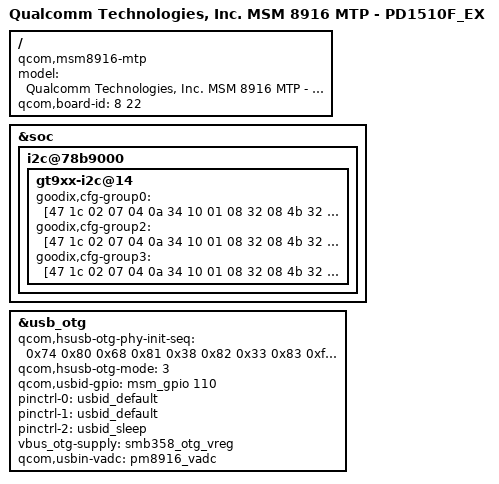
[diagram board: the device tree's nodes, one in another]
/*
 * Copyright (c) 2014-2018, The Linux Foundation. All rights reserved.
 *
 * This program is free software; you can redistribute it and/or modify
 * it under the terms of the GNU General Public License version 2 and
 * only version 2 as published by the Free Software Foundation.
 *
 * This program is distributed in the hope that it will be useful,
 * but WITHOUT ANY WARRANTY; without even the implied warranty of
 * MERCHANTABILITY or FITNESS FOR A PARTICULAR PURPOSE.  See the
 * GNU General Public License for more details.
 */

/dts-v1/;

#include "msm8916-mtp.dtsi"
#include "msm8916-memory.dtsi"
#include "pd1510/msm8916-mtp-pd1510.dtsi"

/ {
	model = "Qualcomm Technologies, Inc. MSM 8916 MTP - PD1510F_EX";
	compatible = "qcom,msm8916-mtp", "qcom,msm8916", "qcom,mtp";
	qcom,board-id = <8 22>;
};

&soc {
	i2c@78b9000 {
		gt9xx-i2c@14 {
			goodix,cfg-group0 = [47 1c 02 07 04 0a 34 10 01 08 32 08 4b 32 33 35 00 00 37 13 00 10 00 14 14 26 14 8c 2c 0d 46 48 d3 07 d3 07 00 99 33 11 00 00 00 00 00 00 00 08 0a a0 21 28 5f 94 d0 02 3c 1e 00 04 d0 2b 00 b1 34 1e 9c 3d 00 88 49 00 78 57 00 78 00 00 00 00 00 00 00 00 00 00 00 00 00 00 00 00 00 00 f7 01 00 00 00 00 00 00 00 00 00 14 50 00 00 00 00 1e 1a 18 16 14 12 10 0e 0c 0a 08 06 04 02 ff 00 00 00 00 00 00 00 00 08 00 00 00 de 00 00 41 16 18 1c 1d 1e 1f 20 21 22 24 26 28 14 13 12 10 0f 0c 0a 08 06 04 02 00 ff ff 00 00 00 00 00 00 00 00 00 00 00 00 00 00 00 00 1e 01];
			goodix,cfg-group2 = [47 1c 02 07 04 0a 34 10 01 08 32 08 4b 32 33 35 00 00 37 13 00 10 00 14 14 26 14 8c 2c 0d 46 48 d3 07 d3 07 00 99 33 11 00 00 00 00 00 00 00 08 0a a0 21 28 5f 94 d0 02 3c 1e 00 04 d0 2b 00 b1 34 1e 9c 3d 00 88 49 00 78 57 00 78 00 00 00 00 00 00 00 00 00 00 00 00 00 00 00 00 00 00 f7 01 00 00 00 00 00 00 00 00 00 14 50 00 00 00 00 1e 1a 18 16 14 12 10 0e 0c 0a 08 06 04 02 ff 00 00 00 00 00 00 00 00 08 00 00 00 de 00 00 41 16 18 1c 1d 1e 1f 20 21 22 24 26 28 14 13 12 10 0f 0c 0a 08 06 04 02 00 ff ff 00 00 00 00 00 00 00 00 00 00 00 00 00 00 00 00 1e 01];
			goodix,cfg-group3 = [47 1c 02 07 04 0a 34 10 01 08 32 08 4b 32 33 35 00 00 37 13 00 10 00 14 14 26 14 8c 2c 0d 46 48 d3 07 d3 07 00 99 33 11 00 00 00 00 00 00 00 08 0a a0 21 28 5f 94 d0 02 3c 1e 00 04 d0 2b 00 b1 34 1e 9c 3d 00 88 49 00 78 57 00 78 00 00 00 00 00 00 00 00 00 00 00 00 00 00 00 00 00 00 f7 01 00 00 00 00 00 00 00 00 00 14 50 00 00 00 00 1e 1a 18 16 14 12 10 0e 0c 0a 08 06 04 02 ff 00 00 00 00 00 00 00 00 08 00 00 00 de 00 00 41 16 18 1c 1d 1e 1f 20 21 22 24 26 28 14 13 12 10 0f 0c 0a 08 06 04 02 00 ff ff 00 00 00 00 00 00 00 00 00 00 00 00 00 00 00 00 1e 01];
		};
	};
};

&usb_otg {
	qcom,hsusb-otg-phy-init-seq = <0x74 0x80 0x68 0x81 0x38 0x82 0x33 0x83 0xffffffff>;
	qcom,hsusb-otg-mode = <3>;
	qcom,usbid-gpio = <&msm_gpio 110 0>;
	pinctrl-names = "default", "active", "sleep";
	pinctrl-0 = <&usbid_default>;
	pinctrl-1 = <&usbid_default>;
	pinctrl-2 = <&usbid_sleep>;
	vbus_otg-supply = <&smb358_otg_vreg>;
	qcom,usbin-vadc = <&pm8916_vadc>;
};
